VERSION ""

NS_ :

BS_:

BU_: XXX

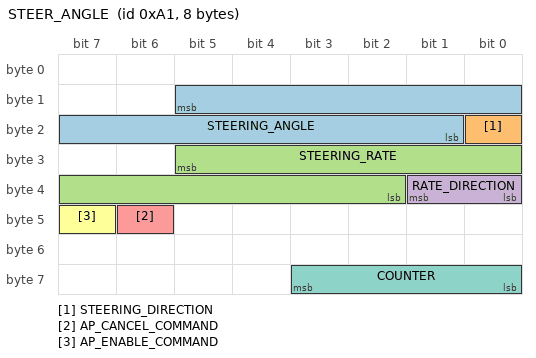
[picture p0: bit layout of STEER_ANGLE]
BO_ 161 STEER_ANGLE: 8 XXX
 SG_ STEERING_ANGLE : 13|13@0+ (0.1,0) [0|819.1] "deg" XXX
 SG_ STEERING_DIRECTION : 16|1@0+ (1,0) [0|1] "" XXX
 SG_ STEERING_RATE : 29|12@0+ (0.004,0) [0|16.38] "deg/s" XXX
 SG_ RATE_DIRECTION : 33|2@0+ (1,0) [0|3] "" XXX
 SG_ AP_CANCEL_COMMAND : 46|1@0+ (1,0) [0|1] "" XXX
 SG_ AP_ENABLE_COMMAND : 47|1@0+ (1,0) [0|1] "" XXX
 SG_ COUNTER : 59|4@0+ (1,0) [0|15] "" XXX

BO_ 315 WHEEL_SPEEDS: 64 XXX
 SG_ WHEEL_SPEED_FL : 12|13@0+ (0.05924739,0) [0|485] "kph" XXX
 SG_ WHEEL_SPEED_FR : 28|13@0+ (0.05924739,0) [0|485] "kph" XXX
 SG_ WHEEL_SPEED_RL : 332|13@0+ (0.05924739,0) [0|485] "kph" XXX
 SG_ WHEEL_SPEED_RR : 348|13@0+ (0.05924739,0) [0|485] "kph" XXX

BO_ 327 STEER_TORQUE: 64 XXX
 SG_ EPS_STEER_REQUESTED : 10|2@0+ (1,0) [0|3] "" XXX
 SG_ DRIVER_TORQUE : 78|11@0- (1,0) [-1024|1023] "" XXX
 SG_ EPS_FAULT_PERMANENT : 125|1@0+ (1,0) [0|1] "" XXX

BO_ 299 STEER_CMD: 64 XXX
 SG_ CRC_COUNTER : 71|8@0+ (1,0) [0|255] "" XXX
 SG_ COUNTER_1 : 123|4@0+ (1,0) [0|15] "" XXX
 SG_ CRC_STEER : 135|8@0+ (1,0) [0|255] "" XXX
 SG_ STEER_REQUEST : 143|14@0+ (0.1,-779.6) [-779.6|858.7] "deg" XXX
 SG_ EPS_LKAS_ANGLE_ENABLE : 175|8@0+ (1,0) [0|255] "" XXX
 SG_ EPS_LKAS_ANGLE_CFG : 183|8@0+ (1,0) [0|255] "" XXX
 SG_ COUNTER_2 : 184|4@1+ (1,0) [0|15] "" XXX

BO_ 323 ACC_CMD: 64 XXX
 SG_ CRC_0 : 7|8@0+ (1,0) [0|255] "" XXX
 SG_ COUNTER_0 : 59|4@0+ (1,0) [0|15] "" XXX
 SG_ CRC_BRAKE : 71|8@0+ (1,0) [0|255] "" XXX
 SG_ BRAKE_OR_GAS_REQ : 76|5@0+ (1,0) [0|31] "" XXX
 SG_ BRAKE_GAS_STATE_2 : 87|18@0+ (1,0) [0|262143] "" XXX
 SG_ STANDSTILL : 101|1@0+ (1,0) [0|1] "" XXX
 SG_ BRAKE_CMD : 111|8@0+ (1,-181) [-181|74] "" XXX
 SG_ SPEED_REAL : 119|8@0+ (1,0) [0|255] "" XXX
 SG_ COUNTER_BRAKE : 123|4@0+ (1,0) [0|15] "" XXX
 SG_ CRC_2 : 135|8@0+ (1,0) [0|255] "" XXX
 SG_ COUNTER_2 : 187|4@0+ (1,0) [0|15] "" XXX
 SG_ CRC_ACC : 199|8@0+ (1,0) [0|255] "" XXX
 SG_ GAS_CMD : 220|13@0+ (1,-192) [-192|4095] "" XXX
 SG_ BRAKE_GAS_STATE : 239|20@0+ (1,0) [0|1048575] "" XXX
 SG_ COUNTER_ACC : 251|4@0+ (1,0) [0|15] "" XXX

BO_ 573 LATERAL_STATE: 64 XXX
 SG_ LKAS_STATE : 141|3@0+ (1,0) [0|7] "" XXX

BO_ 683 ACC: 64 XXX
 SG_ CRUISE_STATE : 149|3@0+ (1,0) [0|7] "" XXX
 SG_ DISTANCE_SELECTION : 170|3@0+ (1,0) [0|7] "" XXX
 SG_ ACC_SPEED_SELECTION : 183|8@0+ (1,0) [0|255] "kph" XXX
 SG_ CRUISE_ENGAGED : 380|1@0+ (1,0) [0|1] "" XXX

BO_ 199 GEAR_STALK: 8 XXX
 SG_ CRC : 7|8@0+ (1,0) [0|255] "" XXX
 SG_ GEAR_STALK_POSITION : 15|8@0+ (1,0) [0|255] "" XXX
 SG_ STALK_DOWN : 14|1@0+ (1,0) [0|1] "" XXX
 SG_ STALK_UP : 13|1@0+ (1,0) [0|1] "" XXX
 SG_ STALK_FURTHER : 12|1@0+ (1,0) [0|1] "" XXX
 SG_ COUNTER : 59|4@0+ (1,0) [0|15] "" XXX

BO_ 545 GEAR: 8 XXX
 SG_ GEAR_REAL : 61|2@0+ (1,0) [0|3] "" XXX

BO_ 288 BRAKE: 64 XXX
 SG_ BRAKE_PRESSED : 11|1@0+ (1,0) [0|1] "" XXX

BO_ 181 GAS: 64 XXX
 SG_ GAS_USER : 247|8@0+ (0.3937,0) [0|100] "%" XXX

BO_ 412 LIGHTS: 16 XXX
 SG_ RIGHT_TURN : 30|1@0+ (1,0) [0|1] "" XXX
 SG_ LEFT_TURN : 31|1@0+ (1,0) [0|1] "" XXX

BO_ 849 SEATBELT: 16 XXX
 SG_ DRIVER_SEATBELT : 11|1@0+ (1,0) [0|1] "" XXX

BO_ 793 DOORS: 16 XXX
 SG_ DRIVER_DOOR : 22|1@0+ (1,0) [0|1] "" XXX

CM_ "GWM Haval H6 PHEV19 2026 (MK4). Minimal working set: the signals CarState
reads plus the STEER_CMD frame CarController writes. Bus assignment matters -
STEER_CMD (299), LATERAL_STATE (573) and ACC (683) are transmitted by the
forward camera and are only visible on the camera bus once the harness relay
opens; everything else is on the main car bus.";

CM_ SG_ 161 STEERING_ANGLE "Absolute wheel angle magnitude, 0.1 deg. Sign is in
STEERING_DIRECTION (1 = right/CW, 0 = left/CCW), applied in carstate. This is
the real angle - message 327 is DRIVER TORQUE, not angle.";
CM_ SG_ 161 STEERING_RATE "Wheel angle rate magnitude; sign is in RATE_DIRECTION
(non-zero = right/CW), applied in carstate.";
CM_ SG_ 299 STEER_REQUEST "Commanded absolute wheel angle. raw = (deg+779.6)*10,
zero at raw 7796. The -779.6 offset is the EPS command-to-wheel transfer, tuned
so the wheel settles on the commanded angle.";
CM_ SG_ 299 CRC_STEER "byte16 = CRC-8 (poly 0x1D, init 0x05) over bytes 17-23.
Recompute on every send. Verified 3002/3002 on an OEM-engaged segment and
2999/2999 on an openpilot-engaged segment.";
CM_ SG_ 299 CRC_COUNTER "byte8 = CRC-8 (poly 0x1D, init 0xD1) over bytes 9-15,
which include COUNTER_1. Recompute whenever COUNTER_1 changes. Same verification
as CRC_STEER.";
CM_ SG_ 299 COUNTER_1 "byte15 low nibble. ALWAYS equal to COUNTER_2 in every
captured frame (3002/3002 and 2999/2999) - the EPS sees a single logical counter
written into two places, each covered by its own CRC. Send both, and increment
from the camera's value.";
CM_ SG_ 299 COUNTER_2 "byte23 low nibble. See COUNTER_1.";
CM_ SG_ 299 EPS_LKAS_ANGLE_ENABLE "byte21: 0x3f = EPS executes STEER_REQUEST,
0x1f = passive/ignore. Set 0x3f only while actively steering; mirror the
camera's value otherwise.";
CM_ SG_ 299 EPS_LKAS_ANGLE_CFG "byte22: 0xe5 active, 0x81 passive.";
CM_ SG_ 327 DRIVER_TORQUE "Driver-applied steering torque, signed. For
override/hands-on detection, NOT vehicle angle.";
CM_ SG_ 327 EPS_STEER_REQUESTED "1 = EPS is executing the camera/openpilot angle,
2 = driver override. NOT a fault indicator - it reads 2 for long stretches of
healthy driving - so it is exposed for diagnostics only and is not wired to any
CarState fault field.";
CM_ SG_ 327 EPS_FAULT_PERMANENT "Toggles 0/1 during normal operation on this
platform, so it is NOT usable as steerFaultPermanent.";
CM_ SG_ 573 LKAS_STATE "5 = lane centering active.";
CM_ SG_ 683 CRUISE_ENGAGED "byte47 bit4. The engagement flag: high through every
labelled ACC and ICC run of the 2026-08-18 differential drive and low outside
them. This is what carstate and the panda safety mode both read, so the two
gates cannot disagree.";
CM_ SG_ 683 CRUISE_STATE "3 = engaged (5 is a brief ICC-engage transient), 1/2 =
not engaged. Corroborates CRUISE_ENGAGED on the same drive; kept for diagnostics.";

VAL_ 545 GEAR_REAL 0 "P" 1 "D" 2 "N" 3 "R" ;
VAL_ 573 LKAS_STATE 5 "active" 2 "hands_on_required" 3 "drift_left" 4 "drift_right" ;
VAL_ 683 CRUISE_STATE 1 "inactive" 2 "available" 3 "engaged" 5 "engaging_icc" ;

CM_ SG_ 199 GEAR_STALK_POSITION "Enumerated stalk position, always a multiple of 15. Measured over 59494 frames: 1 rest, 3 soft UP, 4 hard UP, 5 soft DOWN, 6 hard DOWN. The stock ACC engages on HARD down - every stock engagement in our captures was preceded by one - and ignores SOFT down entirely, which appeared 9 times and never once with cruise engaged. Soft down is therefore usable as openpilot's own engage gesture without ever starting the stock ACC.";
CM_ SG_ 199 STALK_DOWN "Set for both soft and hard down. Pair with STALK_FURTHER to tell them apart.";
CM_ SG_ 199 STALK_FURTHER "The hard detent. DOWN+FURTHER is the stock ACC gesture; DOWN alone is ours.";
CM_ SG_ 199 CRC "crc8 over bytes 1..7, poly 0x1D, init 0xC1. Verified 4000/4000.";
VAL_ 199 GEAR_STALK_POSITION 15 "rest" 45 "soft_up" 60 "hard_up" 75 "soft_down" 90 "hard_down" ;
CM_ SG_ 161 AP_CANCEL_COMMAND "Stalk UP cancel, byte 5 bit 6. Set by both the soft and hard UP gestures. Verified against our captures: present before a stock cruise on->off transition, and on 2026-08-27 it went high 0.07 s after the driver moved the stalk up.";
CM_ SG_ 161 AP_ENABLE_COMMAND "Stalk enable request, byte 5 bit 7. Every stock cruise off->on transition in our captures had it in the prior second. openpilot does not engage on this - it uses the soft-down GEAR_STALK gesture the stock ACC ignores.";
CM_ BO_ 323 "The camera's longitudinal command. FOUR independent CRC blocks, each covering the seven bytes after its check byte, all poly 0x1D - byte0 init 0xF9 over 1..7, byte8 init 0x73 over 9..15, byte16 init 0x3F over 17..23, byte24 init 0x79 over 25..31. Each block ends with a counter nibble at bytes 7, 15, 23, 31. Verified 4000/4000 per block against captured frames. Bytes 56-63 are a MAC and are copied through untouched, as in STEER_CMD.";
CM_ SG_ 323 BRAKE_OR_GAS_REQ "12 = commanding gas, 13 = commanding brake, 8 and 4 = inactive (driver driving), 20 = engaged while the driver is on the accelerator. Measured over 44k frames: 12 and 13 occur only with cruise on, 8 and 4 only with it off, and 20 with cruise on and the throttle pressed 99.7% of the time.";
CM_ SG_ 323 BRAKE_CMD "Brake demand, offset -181. -41 is the brake-OFF baseline the camera sends throughout gas mode; more negative is more braking.";
CM_ SG_ 323 GAS_CMD "Throttle demand, offset -192. Spans byte 27 low 5 bits plus byte 28.";
CM_ SG_ 323 BRAKE_GAS_STATE "The powertrain reads brake-vs-gas STATE from here and from BRAKE_GAS_STATE_2, NOT from BRAKE_OR_GAS_REQ. Regeneration keys off this, so a brake request on top of a copied gas state is a combination the OEM never sends and the motor stays in drive.";
CM_ SG_ 323 SPEED_REAL "UNVERIFIED. Named by an earlier port as km/h, but our captures show only 6 distinct values and byte14=96 spans 48-101 km/h, so it is not the current speed. Do not rely on it.";
